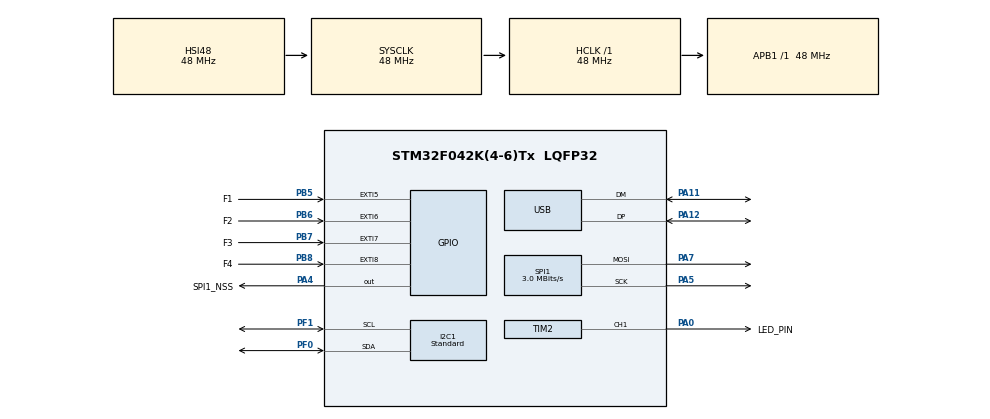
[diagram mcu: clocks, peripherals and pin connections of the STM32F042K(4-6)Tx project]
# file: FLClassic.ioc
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ARM.CMSIS.5.6.0.CMSISOoDriverJjFlash.apiComponent0=Device\:IRQ Controller
ARM.CMSIS.5.6.0.CMSISOoDriverJjFlash.apiComponent1=Device\:OS Tick
ARM.CMSIS.5.6.0.CMSISOoDriverJjFlash.apiComponent10=CMSIS Driver\:SAI
ARM.CMSIS.5.6.0.CMSISOoDriverJjFlash.apiComponent11=CMSIS Driver\:I2C
ARM.CMSIS.5.6.0.CMSISOoDriverJjFlash.apiComponent12=CMSIS Driver\:I2C
ARM.CMSIS.5.6.0.CMSISOoDriverJjFlash.apiComponent13=CMSIS Driver\:CAN
ARM.CMSIS.5.6.0.CMSISOoDriverJjFlash.apiComponent14=CMSIS Driver\:CAN
ARM.CMSIS.5.6.0.CMSISOoDriverJjFlash.apiComponent15=CMSIS Driver\:Flash
ARM.CMSIS.5.6.0.CMSISOoDriverJjFlash.apiComponent16=CMSIS Driver\:Flash
ARM.CMSIS.5.6.0.CMSISOoDriverJjFlash.apiComponent17=CMSIS Driver\:MCI
ARM.CMSIS.5.6.0.CMSISOoDriverJjFlash.apiComponent18=CMSIS Driver\:MCI
ARM.CMSIS.5.6.0.CMSISOoDriverJjFlash.apiComponent19=CMSIS Driver\:NAND
ARM.CMSIS.5.6.0.CMSISOoDriverJjFlash.apiComponent2=CMSIS\:RTOS
ARM.CMSIS.5.6.0.CMSISOoDriverJjFlash.apiComponent20=CMSIS Driver\:NAND
ARM.CMSIS.5.6.0.CMSISOoDriverJjFlash.apiComponent21=CMSIS Driver\:Ethernet
ARM.CMSIS.5.6.0.CMSISOoDriverJjFlash.apiComponent22=CMSIS Driver\:Ethernet
ARM.CMSIS.5.6.0.CMSISOoDriverJjFlash.apiComponent23=CMSIS Driver\:Ethernet
ARM.CMSIS.5.6.0.CMSISOoDriverJjFlash.apiComponent24=CMSIS Driver\:Ethernet MAC
ARM.CMSIS.5.6.0.CMSISOoDriverJjFlash.apiComponent25=CMSIS Driver\:Ethernet MAC
ARM.CMSIS.5.6.0.CMSISOoDriverJjFlash.apiComponent26=CMSIS Driver\:Ethernet PHY
ARM.CMSIS.5.6.0.CMSISOoDriverJjFlash.apiComponent27=CMSIS Driver\:Ethernet PHY
ARM.CMSIS.5.6.0.CMSISOoDriverJjFlash.apiComponent28=CMSIS Driver\:USB Device
ARM.CMSIS.5.6.0.CMSISOoDriverJjFlash.apiComponent29=CMSIS Driver\:USB Device
ARM.CMSIS.5.6.0.CMSISOoDriverJjFlash.apiComponent3=CMSIS\:RTOS2
ARM.CMSIS.5.6.0.CMSISOoDriverJjFlash.apiComponent30=CMSIS Driver\:USB Host
ARM.CMSIS.5.6.0.CMSISOoDriverJjFlash.apiComponent31=CMSIS Driver\:USB Host
ARM.CMSIS.5.6.0.CMSISOoDriverJjFlash.apiComponent32=CMSIS Driver\:WiFi
ARM.CMSIS.5.6.0.CMSISOoDriverJjFlash.apiComponent33=CMSIS Driver\:WiFi
ARM.CMSIS.5.6.0.CMSISOoDriverJjFlash.apiComponent4=CMSIS\:RTOS2
ARM.CMSIS.5.6.0.CMSISOoDriverJjFlash.apiComponent5=CMSIS Driver\:USART
ARM.CMSIS.5.6.0.CMSISOoDriverJjFlash.apiComponent6=CMSIS Driver\:USART
ARM.CMSIS.5.6.0.CMSISOoDriverJjFlash.apiComponent7=CMSIS Driver\:SPI
ARM.CMSIS.5.6.0.CMSISOoDriverJjFlash.apiComponent8=CMSIS Driver\:SPI
ARM.CMSIS.5.6.0.CMSISOoDriverJjFlash.apiComponent9=CMSIS Driver\:SAI
ARM.CMSIS.5.6.0.CMSISOoDriverJjFlash.apiDoc0=CMSIS/Core_A/Include/irq_ctrl.h
ARM.CMSIS.5.6.0.CMSISOoDriverJjFlash.apiDoc1=CMSIS/RTOS2/Include/os_tick.h
ARM.CMSIS.5.6.0.CMSISOoDriverJjFlash.apiDoc10=CMSIS/Driver/Include/Driver_SAI.h
ARM.CMSIS.5.6.0.CMSISOoDriverJjFlash.apiDoc11=CMSIS/Documentation/Driver/html/group__i2c__interface__gr.html
ARM.CMSIS.5.6.0.CMSISOoDriverJjFlash.apiDoc12=CMSIS/Driver/Include/Driver_I2C.h
ARM.CMSIS.5.6.0.CMSISOoDriverJjFlash.apiDoc13=CMSIS/Documentation/Driver/html/group__can__interface__gr.html
ARM.CMSIS.5.6.0.CMSISOoDriverJjFlash.apiDoc14=CMSIS/Driver/Include/Driver_CAN.h
ARM.CMSIS.5.6.0.CMSISOoDriverJjFlash.apiDoc15=CMSIS/Documentation/Driver/html/group__flash__interface__gr.html
ARM.CMSIS.5.6.0.CMSISOoDriverJjFlash.apiDoc16=CMSIS/Driver/Include/Driver_Flash.h
ARM.CMSIS.5.6.0.CMSISOoDriverJjFlash.apiDoc17=CMSIS/Documentation/Driver/html/group__mci__interface__gr.html
ARM.CMSIS.5.6.0.CMSISOoDriverJjFlash.apiDoc18=CMSIS/Driver/Include/Driver_MCI.h
ARM.CMSIS.5.6.0.CMSISOoDriverJjFlash.apiDoc19=CMSIS/Documentation/Driver/html/group__nand__interface__gr.html
ARM.CMSIS.5.6.0.CMSISOoDriverJjFlash.apiDoc2=CMSIS/Documentation/RTOS/html/index.html
ARM.CMSIS.5.6.0.CMSISOoDriverJjFlash.apiDoc20=CMSIS/Driver/Include/Driver_NAND.h
ARM.CMSIS.5.6.0.CMSISOoDriverJjFlash.apiDoc21=CMSIS/Documentation/Driver/html/group__eth__interface__gr.html
ARM.CMSIS.5.6.0.CMSISOoDriverJjFlash.apiDoc22=CMSIS/Driver/Include/Driver_ETH_MAC.h
ARM.CMSIS.5.6.0.CMSISOoDriverJjFlash.apiDoc23=CMSIS/Driver/Include/Driver_ETH_PHY.h
ARM.CMSIS.5.6.0.CMSISOoDriverJjFlash.apiDoc24=CMSIS/Documentation/Driver/html/group__eth__mac__interface__gr.html
ARM.CMSIS.5.6.0.CMSISOoDriverJjFlash.apiDoc25=CMSIS/Driver/Include/Driver_ETH_MAC.h
ARM.CMSIS.5.6.0.CMSISOoDriverJjFlash.apiDoc26=CMSIS/Documentation/Driver/html/group__eth__phy__interface__gr.html
ARM.CMSIS.5.6.0.CMSISOoDriverJjFlash.apiDoc27=CMSIS/Driver/Include/Driver_ETH_PHY.h
ARM.CMSIS.5.6.0.CMSISOoDriverJjFlash.apiDoc28=CMSIS/Documentation/Driver/html/group__usbd__interface__gr.html
ARM.CMSIS.5.6.0.CMSISOoDriverJjFlash.apiDoc29=CMSIS/Driver/Include/Driver_USBD.h
ARM.CMSIS.5.6.0.CMSISOoDriverJjFlash.apiDoc3=CMSIS/Documentation/RTOS2/html/index.html
ARM.CMSIS.5.6.0.CMSISOoDriverJjFlash.apiDoc30=CMSIS/Documentation/Driver/html/group__usbh__interface__gr.html
ARM.CMSIS.5.6.0.CMSISOoDriverJjFlash.apiDoc31=CMSIS/Driver/Include/Driver_USBH.h
ARM.CMSIS.5.6.0.CMSISOoDriverJjFlash.apiDoc32=CMSIS/Documentation/Driver/html/group__wifi__interface__gr.html
ARM.CMSIS.5.6.0.CMSISOoDriverJjFlash.apiDoc33=CMSIS/Driver/Include/Driver_WiFi.h
ARM.CMSIS.5.6.0.CMSISOoDriverJjFlash.apiDoc4=CMSIS/RTOS2/Include/cmsis_os2.h
ARM.CMSIS.5.6.0.CMSISOoDriverJjFlash.apiDoc5=CMSIS/Documentation/Driver/html/group__usart__interface__gr.html
ARM.CMSIS.5.6.0.CMSISOoDriverJjFlash.apiDoc6=CMSIS/Driver/Include/Driver_USART.h
ARM.CMSIS.5.6.0.CMSISOoDriverJjFlash.apiDoc7=CMSIS/Documentation/Driver/html/group__spi__interface__gr.html
ARM.CMSIS.5.6.0.CMSISOoDriverJjFlash.apiDoc8=CMSIS/Driver/Include/Driver_SPI.h
ARM.CMSIS.5.6.0.CMSISOoDriverJjFlash.apiDoc9=CMSIS/Documentation/Driver/html/group__sai__interface__gr.html
ARM.CMSIS.5.6.0.CMSISOoDriverJjFlash.cmp_version0=2.2.0
ARM.CMSIS.5.6.0.CMSISOoDriverJjFlash.component0=CMSIS Driver
ARM.CMSIS.5.6.0.CMSISOoDriverJjFlash.description0=Access to \#include Driver_Flash.h file and code template for custom implementation
ARM.CMSIS.5.6.0.CMSISOoDriverJjFlash.diagnostic0=This component should operate correctly.
ARM.CMSIS.5.6.0.CMSISOoDriverJjFlash.group0=Flash
ARM.CMSIS.5.6.0.CMSISOoDriverJjFlash.paramName0=CMSISOoDriverJjFlashJjCustom
ARM.CMSIS.5.6.0.CMSISOoDriverJjFlash.sevirity0=none
ARM.CMSIS.5.6.0.CMSISOoDriverJjFlash.sub-group0=Custom
ARM.CMSIS.5.6.0.CMSISOoDriverJjFlashJjCustom=true
ARM.CMSIS.5.6.0.CMSISOoDriverJjFlash_apiSize=34
ARM.CMSIS.5.6.0.CMSISOoDriverJjFlash_bundle=CMSIS
ARM.CMSIS.5.6.0.CMSISOoDriverJjFlash_class=CMSISOoDriver
ARM.CMSIS.5.6.0.CMSISOoDriverJjFlash_name=CMSIS
ARM.CMSIS.5.6.0.CMSISOoDriverJjFlash_size=1
ARM.CMSIS.5.6.0.CMSISOoDriverJjFlash_vendor=ARM
ARM.CMSIS.5.6.0.CMSISOoDriverJjFlash_version=5.6.0
ARM.CMSIS.5.6.0_CMSISJjCORE_RteComponentsize=0
ARM.CMSIS.5.6.0_CMSISJjDSP_RteComponentsize=0
ARM.CMSIS.5.6.0_CMSISJjNNOoLib_RteComponentsize=0
ARM.CMSIS.5.6.0_CMSISJjRTOS2_RteComponentsize=0
ARM.CMSIS.5.6.0_CMSISJjRTOS_RteComponentsize=0
ARM.CMSIS.5.6.0_CMSISOoDriverJjCAN_RteComponentsize=0
ARM.CMSIS.5.6.0_CMSISOoDriverJjEthernetOoMAC_RteComponentsize=0
ARM.CMSIS.5.6.0_CMSISOoDriverJjEthernetOoPHY_RteComponentsize=0
ARM.CMSIS.5.6.0_CMSISOoDriverJjEthernet_RteComponentsize=0
ARM.CMSIS.5.6.0_CMSISOoDriverJjFlash_RteComponentsize=0
ARM.CMSIS.5.6.0_CMSISOoDriverJjI2C_RteComponentsize=0
ARM.CMSIS.5.6.0_CMSISOoDriverJjMCI_RteComponentsize=0
ARM.CMSIS.5.6.0_CMSISOoDriverJjNAND_RteComponentsize=0
ARM.CMSIS.5.6.0_CMSISOoDriverJjSAI_RteComponentsize=0
ARM.CMSIS.5.6.0_CMSISOoDriverJjSPI_RteComponentsize=0
ARM.CMSIS.5.6.0_CMSISOoDriverJjUSART_RteComponentsize=0
ARM.CMSIS.5.6.0_CMSISOoDriverJjUSBOoDevice_RteComponentsize=0
ARM.CMSIS.5.6.0_CMSISOoDriverJjUSBOoHost_RteComponentsize=0
ARM.CMSIS.5.6.0_CMSISOoDriverJjWiFi_RteComponentsize=0
ARM.CMSIS.5.6.0_DeviceJjIRQOoController_RteComponentsize=0
ARM.CMSIS.5.6.0_DeviceJjOSOoTick_RteComponentsize=0
ARM.CMSIS.5.6.0_DeviceJjStartup_RteComponentsize=0
ARM.CMSIS.5.6.0_description=CMSIS (Cortex Microcontroller Software Interface Standard)
Dma.Request0=TIM2_CH1
Dma.Request1=SPI1_TX
Dma.SPI1_TX.1.Direction=DMA_MEMORY_TO_PERIPH
Dma.SPI1_TX.1.Instance=DMA1_Channel3
Dma.SPI1_TX.1.MemDataAlignment=DMA_MDATAALIGN_BYTE
Dma.SPI1_TX.1.MemInc=DMA_MINC_ENABLE
Dma.SPI1_TX.1.Mode=DMA_NORMAL
Dma.SPI1_TX.1.PeriphDataAlignment=DMA_PDATAALIGN_BYTE
Dma.SPI1_TX.1.PeriphInc=DMA_PINC_DISABLE
Dma.SPI1_TX.1.Priority=DMA_PRIORITY_LOW
Dma.TIM2_CH1.0.Direction=DMA_MEMORY_TO_PERIPH
Dma.TIM2_CH1.0.Instance=DMA1_Channel5
Dma.TIM2_CH1.0.MemDataAlignment=DMA_MDATAALIGN_BYTE
Dma.TIM2_CH1.0.MemInc=DMA_MINC_ENABLE
Dma.TIM2_CH1.0.Mode=DMA_CIRCULAR
Dma.TIM2_CH1.0.PeriphDataAlignment=DMA_PDATAALIGN_WORD
Dma.TIM2_CH1.0.PeriphInc=DMA_PINC_DISABLE
Dma.TIM2_CH1.0.Priority=DMA_PRIORITY_HIGH
I2C1.I2C_Speed_Mode=I2C_Standard
I2C1.Timing=0x2000090E
Mcu.Family=STM32F0
Mcu.Name=STM32F042K(4-6)Tx
Mcu.Package=LQFP32
NVIC.DMA1_Channel2_3_IRQn=true\:0\:0\:false\:false\:true\:false\:true
NVIC.DMA1_Channel4_5_IRQn=true\:0\:0\:false\:false\:true\:false\:true
NVIC.EXTI4_15_IRQn=true\:0\:0\:false\:false\:true\:true\:true
NVIC.TIM16_IRQn=true\:0\:0\:false\:false\:true\:true\:true
NVIC.USB_IRQn=true\:0\:0\:false\:false\:true\:false\:true
PA0.GPIO_Label=LED_PIN
PA0.Signal=S_TIM2_CH1_ETR
PA11.Mode=Device
PA11.Signal=USB_DM
PA12.Mode=Device
PA12.Signal=USB_DP
PA13.Mode=Serial_Wire
PA13.Signal=SYS_SWDIO
PA14.Mode=Serial_Wire
PA14.Signal=SYS_SWCLK
PA4.GPIO_Label=SPI1_NSS
PA4.Signal=GPIO_Output
PA5.Mode=TX_Only_Simplex_Unidirect_Master
PA5.Signal=SPI1_SCK
PA7.Mode=TX_Only_Simplex_Unidirect_Master
PA7.Signal=SPI1_MOSI
PB5.GPIO_Label=F1
PB5.GPIO_ModeDefaultEXTI=GPIO_MODE_IT_RISING_FALLING
PB5.GPIO_PuPd=GPIO_PULLUP
PB5.Signal=GPXTI5
PB6.GPIO_Label=F2
PB6.GPIO_ModeDefaultEXTI=GPIO_MODE_IT_RISING_FALLING
PB6.GPIO_PuPd=GPIO_PULLUP
PB6.Signal=GPXTI6
PB7.GPIO_Label=F3
PB7.GPIO_ModeDefaultEXTI=GPIO_MODE_IT_RISING_FALLING
PB7.GPIO_PuPd=GPIO_PULLUP
PB7.Signal=GPXTI7
PB8.GPIO_Label=F4
PB8.GPIO_ModeDefaultEXTI=GPIO_MODE_IT_RISING_FALLING
PB8.GPIO_PuPd=GPIO_PULLUP
PB8.Signal=GPXTI8
PF0-OSC_IN.Mode=I2C
PF0-OSC_IN.Signal=I2C1_SDA
PF1-OSC_OUT.Mode=I2C
PF1-OSC_OUT.Signal=I2C1_SCL
ProjectManager.HeapSize=0x000
ProjectManager.StackSize=0x200
ProjectManager.TargetToolchain=SW4STM32
RCC.AHBFreq_Value=48000000
RCC.APB1Freq_Value=48000000
RCC.APB1TimFreq_Value=48000000
RCC.HCLKFreq_Value=48000000
RCC.SYSCLKFreq_VALUE=48000000
RCC.SYSCLKSource=RCC_SYSCLKSOURCE_HSI48
SH.S_TIM2_CH1_ETR.0=TIM2_CH1,PWM Generation1 CH1
SPI1.BaudRatePrescaler=SPI_BAUDRATEPRESCALER_16
SPI1.CLKPhase=SPI_PHASE_2EDGE
SPI1.CLKPolarity=SPI_POLARITY_HIGH
SPI1.CalculateBaudRate=3.0 MBits/s
SPI1.DataSize=SPI_DATASIZE_8BIT
SPI1.Direction=SPI_DIRECTION_2LINES
SPI1.FirstBit=SPI_FIRSTBIT_LSB
SPI1.Mode=SPI_MODE_MASTER
SPI1.VirtualType=VM_MASTER
TIM14.AutoReloadPreload=TIM_AUTORELOAD_PRELOAD_ENABLE
TIM14.Period=1200-1
TIM14.Prescaler=48000-1
TIM16.Period=1
TIM16.Prescaler=20000-1
TIM2.AutoReloadPreload=TIM_AUTORELOAD_PRELOAD_DISABLE
TIM2.Channel-PWM\ Generation1\ CH1=TIM_CHANNEL_1
TIM2.OCMode_PWM-PWM\ Generation1\ CH1=TIM_OCMODE_PWM1
TIM2.OCPolarity_1=TIM_OCPOLARITY_HIGH
TIM2.Period=60-1
USB_DEVICE.APP_RX_DATA_SIZE=40
USB_DEVICE.APP_TX_DATA_SIZE=20
USB_DEVICE.CLASS_NAME_FS=CDC
USB_DEVICE.USBD_MAX_STR_DESC_SIZ=32
USB_DEVICE.USBD_SELF_POWERED=0
USB_DEVICE.VirtualMode=Cdc
USB_DEVICE.VirtualModeFS=Cdc_FS
VP_TIM14_VS_ClockSourceINT.Mode=Enable_Timer
VP_TIM16_VS_ClockSourceINT.Mode=Enable_Timer
VP_TIM2_VS_ClockSourceINT.Mode=Internal
VP_USB_DEVICE_VS_USB_DEVICE_CDC_FS.Mode=CDC_FS
board=custom

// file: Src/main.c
/* USER CODE BEGIN Header */
/**
  ******************************************************************************
  * @file           : main.c
  * @brief          : Main program body
  ******************************************************************************
  * @attention
  *
  * <h2><center>&copy; Copyright (c) 2019 STMicroelectronics.
  * All rights reserved.</center></h2>
  *
  * This software component is licensed by ST under Ultimate Liberty license
  * SLA0044, the "License"; You may not use this file except in compliance with
  * the License. You may obtain a copy of the License at:
  *                             www.st.com/SLA0044
  *
  ******************************************************************************
  */
/* USER CODE END Header */

#include "main.h"
#include "usb_device.h"

/* USER CODE BEGIN Includes */
#include "../../Commons/vfdco_clock_routines.h"
/* USER CODE END Includes */

I2C_HandleTypeDef hi2c1;

SPI_HandleTypeDef hspi1;
DMA_HandleTypeDef hdma_spi1_tx;

TIM_HandleTypeDef htim2;
TIM_HandleTypeDef htim14;
TIM_HandleTypeDef htim16;
DMA_HandleTypeDef hdma_tim2_ch1;

void SystemClock_Config(void);
static void MX_GPIO_Init(void);
static void MX_TIM2_Init(void);
static void MX_DMA_Init(void);
static void MX_TIM14_Init(void);
static void MX_I2C1_Init(void);
static void MX_SPI1_Init(void);
static void MX_TIM16_Init(void);

int main(void)
{

  /* MCU Configuration--------------------------------------------------------*/

  /* Reset of all peripherals, Initializes the Flash interface and the Systick. */
  HAL_Init();

  /* Configure the system clock */
  SystemClock_Config();

  /* Initialize all configured peripherals */
  MX_GPIO_Init();
  MX_DMA_Init();
  MX_TIM2_Init();
  MX_TIM14_Init();
  MX_I2C1_Init();
  MX_SPI1_Init();
  MX_TIM16_Init();
  MX_USB_DEVICE_Init();
  /* USER CODE BEGIN 2 */

  // Initialize clock
  vfdco_clock_initializer();

  /* USER CODE END 2 */

  /* Infinite loop */
  while (1)
  {

    /* USER CODE BEGIN 3 */

  	// WoHOo hOw FuN iS tHhIis??
  	vfdco_clock_routine();
  	// vfdco_clock_com_routine();

  }
  /* USER CODE END 3 */
}

void SystemClock_Config(void)
{
  RCC_OscInitTypeDef RCC_OscInitStruct = {0};
  RCC_ClkInitTypeDef RCC_ClkInitStruct = {0};
  RCC_PeriphCLKInitTypeDef PeriphClkInit = {0};

  /** Initializes the CPU, AHB and APB busses clocks
  */
  RCC_OscInitStruct.OscillatorType = RCC_OSCILLATORTYPE_HSI|RCC_OSCILLATORTYPE_HSI48;
  RCC_OscInitStruct.HSIState = RCC_HSI_ON;
  RCC_OscInitStruct.HSI48State = RCC_HSI48_ON;
  RCC_OscInitStruct.HSICalibrationValue = RCC_HSICALIBRATION_DEFAULT;
  RCC_OscInitStruct.PLL.PLLState = RCC_PLL_NONE;
  if (HAL_RCC_OscConfig(&RCC_OscInitStruct) != HAL_OK)
  {
    Error_Handler();
  }
  /** Initializes the CPU, AHB and APB busses clocks
  */
  RCC_ClkInitStruct.ClockType = RCC_CLOCKTYPE_HCLK|RCC_CLOCKTYPE_SYSCLK
                              |RCC_CLOCKTYPE_PCLK1;
  RCC_ClkInitStruct.SYSCLKSource = RCC_SYSCLKSOURCE_HSI48;
  RCC_ClkInitStruct.AHBCLKDivider = RCC_SYSCLK_DIV1;
  RCC_ClkInitStruct.APB1CLKDivider = RCC_HCLK_DIV1;

  if (HAL_RCC_ClockConfig(&RCC_ClkInitStruct, FLASH_LATENCY_1) != HAL_OK)
  {
    Error_Handler();
  }
  PeriphClkInit.PeriphClockSelection = RCC_PERIPHCLK_USB|RCC_PERIPHCLK_I2C1;
  PeriphClkInit.I2c1ClockSelection = RCC_I2C1CLKSOURCE_HSI;
  PeriphClkInit.UsbClockSelection = RCC_USBCLKSOURCE_HSI48;

  if (HAL_RCCEx_PeriphCLKConfig(&PeriphClkInit) != HAL_OK)
  {
    Error_Handler();
  }
}

static void MX_I2C1_Init(void)
{

  hi2c1.Instance = I2C1;
  hi2c1.Init.Timing = 0x2000090E;
  hi2c1.Init.OwnAddress1 = 0;
  hi2c1.Init.AddressingMode = I2C_ADDRESSINGMODE_7BIT;
  hi2c1.Init.DualAddressMode = I2C_DUALADDRESS_DISABLE;
  hi2c1.Init.OwnAddress2 = 0;
  hi2c1.Init.OwnAddress2Masks = I2C_OA2_NOMASK;
  hi2c1.Init.GeneralCallMode = I2C_GENERALCALL_DISABLE;
  hi2c1.Init.NoStretchMode = I2C_NOSTRETCH_DISABLE;
  if (HAL_I2C_Init(&hi2c1) != HAL_OK)
  {
    Error_Handler();
  }
  /** Configure Analogue filter
  */
  if (HAL_I2CEx_ConfigAnalogFilter(&hi2c1, I2C_ANALOGFILTER_ENABLE) != HAL_OK)
  {
    Error_Handler();
  }
  /** Configure Digital filter
  */
  if (HAL_I2CEx_ConfigDigitalFilter(&hi2c1, 0) != HAL_OK)
  {
    Error_Handler();
  }

}

static void MX_SPI1_Init(void)
{

  /* SPI1 parameter configuration*/
  hspi1.Instance = SPI1;
  hspi1.Init.Mode = SPI_MODE_MASTER;
  hspi1.Init.Direction = SPI_DIRECTION_2LINES;
  hspi1.Init.DataSize = SPI_DATASIZE_8BIT;
  hspi1.Init.CLKPolarity = SPI_POLARITY_HIGH;
  hspi1.Init.CLKPhase = SPI_PHASE_2EDGE;
  hspi1.Init.NSS = SPI_NSS_SOFT;
  hspi1.Init.BaudRatePrescaler = SPI_BAUDRATEPRESCALER_16;
  hspi1.Init.FirstBit = SPI_FIRSTBIT_LSB;
  hspi1.Init.TIMode = SPI_TIMODE_DISABLE;
  hspi1.Init.CRCCalculation = SPI_CRCCALCULATION_DISABLE;
  hspi1.Init.CRCPolynomial = 7;
  hspi1.Init.CRCLength = SPI_CRC_LENGTH_DATASIZE;
  hspi1.Init.NSSPMode = SPI_NSS_PULSE_DISABLE;
  if (HAL_SPI_Init(&hspi1) != HAL_OK)
  {
    Error_Handler();
  }

}

static void MX_TIM2_Init(void)
{

  TIM_ClockConfigTypeDef sClockSourceConfig = {0};
  TIM_MasterConfigTypeDef sMasterConfig = {0};
  TIM_OC_InitTypeDef sConfigOC = {0};

  htim2.Instance = TIM2;
  htim2.Init.Prescaler = 0;
  htim2.Init.CounterMode = TIM_COUNTERMODE_UP;
  htim2.Init.Period = 60-1;
  htim2.Init.ClockDivision = TIM_CLOCKDIVISION_DIV1;
  htim2.Init.AutoReloadPreload = TIM_AUTORELOAD_PRELOAD_DISABLE;
  if (HAL_TIM_Base_Init(&htim2) != HAL_OK)
  {
    Error_Handler();
  }
  sClockSourceConfig.ClockSource = TIM_CLOCKSOURCE_INTERNAL;
  if (HAL_TIM_ConfigClockSource(&htim2, &sClockSourceConfig) != HAL_OK)
  {
    Error_Handler();
  }
  if (HAL_TIM_PWM_Init(&htim2) != HAL_OK)
  {
    Error_Handler();
  }
  sMasterConfig.MasterOutputTrigger = TIM_TRGO_RESET;
  sMasterConfig.MasterSlaveMode = TIM_MASTERSLAVEMODE_DISABLE;
  if (HAL_TIMEx_MasterConfigSynchronization(&htim2, &sMasterConfig) != HAL_OK)
  {
    Error_Handler();
  }
  sConfigOC.OCMode = TIM_OCMODE_PWM1;
  sConfigOC.Pulse = 0;
  sConfigOC.OCPolarity = TIM_OCPOLARITY_HIGH;
  sConfigOC.OCFastMode = TIM_OCFAST_DISABLE;
  if (HAL_TIM_PWM_ConfigChannel(&htim2, &sConfigOC, TIM_CHANNEL_1) != HAL_OK)
  {
    Error_Handler();
  }
  HAL_TIM_MspPostInit(&htim2);

}

static void MX_TIM14_Init(void)
{

  htim14.Instance = TIM14;
  htim14.Init.Prescaler = 48000-1;
  htim14.Init.CounterMode = TIM_COUNTERMODE_UP;
  htim14.Init.Period = 1200-1;
  htim14.Init.ClockDivision = TIM_CLOCKDIVISION_DIV1;
  htim14.Init.AutoReloadPreload = TIM_AUTORELOAD_PRELOAD_ENABLE;
  if (HAL_TIM_Base_Init(&htim14) != HAL_OK)
  {
    Error_Handler();
  }

}

static void MX_TIM16_Init(void)
{

  htim16.Instance = TIM16;
  htim16.Init.Prescaler = 20000-1;
  htim16.Init.CounterMode = TIM_COUNTERMODE_UP;
  htim16.Init.Period = 1;
  htim16.Init.ClockDivision = TIM_CLOCKDIVISION_DIV1;
  htim16.Init.RepetitionCounter = 0;
  htim16.Init.AutoReloadPreload = TIM_AUTORELOAD_PRELOAD_DISABLE;
  if (HAL_TIM_Base_Init(&htim16) != HAL_OK)
  {
    Error_Handler();
  }

}

static void MX_DMA_Init(void)
{

  /* DMA controller clock enable */
  __HAL_RCC_DMA1_CLK_ENABLE();

  /* DMA interrupt init */
  /* DMA1_Channel2_3_IRQn interrupt configuration */
  HAL_NVIC_SetPriority(DMA1_Channel2_3_IRQn, 0, 0);
  HAL_NVIC_EnableIRQ(DMA1_Channel2_3_IRQn);
  /* DMA1_Channel4_5_IRQn interrupt configuration */
  HAL_NVIC_SetPriority(DMA1_Channel4_5_IRQn, 0, 0);
  HAL_NVIC_EnableIRQ(DMA1_Channel4_5_IRQn);

}

static void MX_GPIO_Init(void)
{
  GPIO_InitTypeDef GPIO_InitStruct = {0};

  /* GPIO Ports Clock Enable */
  __HAL_RCC_GPIOF_CLK_ENABLE();
  __HAL_RCC_GPIOA_CLK_ENABLE();
  __HAL_RCC_GPIOB_CLK_ENABLE();

  /*Configure GPIO pin Output Level */
  HAL_GPIO_WritePin(SPI1_NSS_GPIO_Port, SPI1_NSS_Pin, GPIO_PIN_RESET);

  /*Configure GPIO pins : PA1 PA2 PA3 PA6
                           PA8 PA9 PA10 PA15 */
  GPIO_InitStruct.Pin = GPIO_PIN_1|GPIO_PIN_2|GPIO_PIN_3|GPIO_PIN_6
                          |GPIO_PIN_8|GPIO_PIN_9|GPIO_PIN_10|GPIO_PIN_15;
  GPIO_InitStruct.Mode = GPIO_MODE_ANALOG;
  GPIO_InitStruct.Pull = GPIO_NOPULL;
  HAL_GPIO_Init(GPIOA, &GPIO_InitStruct);

  /*Configure GPIO pin : SPI1_NSS_Pin */
  GPIO_InitStruct.Pin = SPI1_NSS_Pin;
  GPIO_InitStruct.Mode = GPIO_MODE_OUTPUT_PP;
  GPIO_InitStruct.Pull = GPIO_NOPULL;
  GPIO_InitStruct.Speed = GPIO_SPEED_FREQ_LOW;
  HAL_GPIO_Init(SPI1_NSS_GPIO_Port, &GPIO_InitStruct);

  /*Configure GPIO pins : PB0 PB1 PB3 PB4 */
  GPIO_InitStruct.Pin = GPIO_PIN_0|GPIO_PIN_1|GPIO_PIN_3|GPIO_PIN_4;
  GPIO_InitStruct.Mode = GPIO_MODE_ANALOG;
  GPIO_InitStruct.Pull = GPIO_NOPULL;
  HAL_GPIO_Init(GPIOB, &GPIO_InitStruct);

  /*Configure GPIO pins : F1_Pin F2_Pin F3_Pin F4_Pin */
  GPIO_InitStruct.Pin = F1_Pin|F2_Pin|F3_Pin|F4_Pin;
  GPIO_InitStruct.Mode = GPIO_MODE_IT_RISING_FALLING;
  GPIO_InitStruct.Pull = GPIO_PULLUP;
  HAL_GPIO_Init(GPIOB, &GPIO_InitStruct);

  /* EXTI interrupt init*/
  HAL_NVIC_SetPriority(EXTI4_15_IRQn, 0, 0);
  HAL_NVIC_EnableIRQ(EXTI4_15_IRQn);

}

void Error_Handler(void)
{
}

/************************ (C) COPYRIGHT STMicroelectronics *****END OF FILE****/
